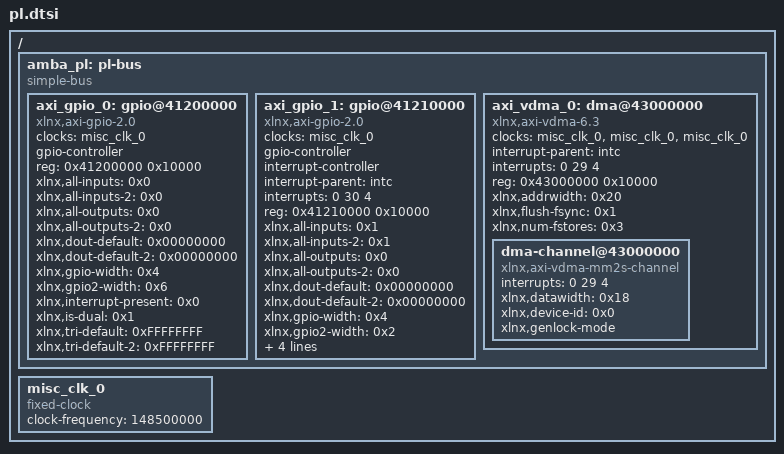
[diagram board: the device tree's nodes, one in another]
/*
 * CAUTION: This file is automatically generated by Xilinx.
 * Version: XSCT 2024.1
 * Today is: Mon Sep 22 18:21:32 2025
 */


/ {
	amba_pl: pl-bus {
		#address-cells = <1>;
		#size-cells = <1>;
		compatible = "simple-bus";
		ranges ;
		axi_gpio_0: gpio@41200000 {
			#gpio-cells = <2>;
			clock-names = "s_axi_aclk";
			clocks = <&misc_clk_0>;
			compatible = "xlnx,axi-gpio-2.0", "xlnx,xps-gpio-1.00.a";
			gpio-controller ;
			reg = <0x41200000 0x10000>;
			xlnx,all-inputs = <0x0>;
			xlnx,all-inputs-2 = <0x0>;
			xlnx,all-outputs = <0x0>;
			xlnx,all-outputs-2 = <0x0>;
			xlnx,dout-default = <0x00000000>;
			xlnx,dout-default-2 = <0x00000000>;
			xlnx,gpio-width = <0x4>;
			xlnx,gpio2-width = <0x6>;
			xlnx,interrupt-present = <0x0>;
			xlnx,is-dual = <0x1>;
			xlnx,tri-default = <0xFFFFFFFF>;
			xlnx,tri-default-2 = <0xFFFFFFFF>;
		};
		axi_gpio_1: gpio@41210000 {
			#gpio-cells = <2>;
			#interrupt-cells = <2>;
			clock-names = "s_axi_aclk";
			clocks = <&misc_clk_0>;
			compatible = "xlnx,axi-gpio-2.0", "xlnx,xps-gpio-1.00.a";
			gpio-controller ;
			interrupt-controller ;
			interrupt-names = "ip2intc_irpt";
			interrupt-parent = <&intc>;
			interrupts = <0 30 4>;
			reg = <0x41210000 0x10000>;
			xlnx,all-inputs = <0x1>;
			xlnx,all-inputs-2 = <0x1>;
			xlnx,all-outputs = <0x0>;
			xlnx,all-outputs-2 = <0x0>;
			xlnx,dout-default = <0x00000000>;
			xlnx,dout-default-2 = <0x00000000>;
			xlnx,gpio-width = <0x4>;
			xlnx,gpio2-width = <0x2>;
			xlnx,interrupt-present = <0x1>;
			xlnx,is-dual = <0x1>;
			xlnx,tri-default = <0xFFFFFFFF>;
			xlnx,tri-default-2 = <0xFFFFFFFF>;
		};
		axi_vdma_0: dma@43000000 {
			#dma-cells = <1>;
			clock-names = "m_axi_mm2s_aclk", "m_axis_mm2s_aclk", "s_axi_lite_aclk";
			clocks = <&misc_clk_0>, <&misc_clk_0>, <&misc_clk_0>;
			compatible = "xlnx,axi-vdma-6.3", "xlnx,axi-vdma-1.00.a";
			interrupt-names = "mm2s_introut";
			interrupt-parent = <&intc>;
			interrupts = <0 29 4>;
			reg = <0x43000000 0x10000>;
			xlnx,addrwidth = <0x20>;
			xlnx,flush-fsync = <0x1>;
			xlnx,num-fstores = <0x3>;
			dma-channel@43000000 {
				compatible = "xlnx,axi-vdma-mm2s-channel";
				interrupts = <0 29 4>;
				xlnx,datawidth = <0x18>;
				xlnx,device-id = <0x0>;
				xlnx,genlock-mode ;
			};
		};
	};
	misc_clk_0: misc_clk_0 {
		#clock-cells = <0>;
		clock-frequency = <148500000>;
		compatible = "fixed-clock";
	};
};
